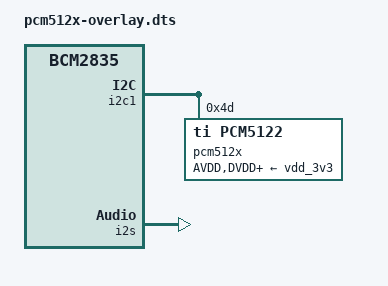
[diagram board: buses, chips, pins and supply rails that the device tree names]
/dts-v1/;
/plugin/;

/ {
    compatible = "brcm,bcm2835";

    fragment@0 {
        target = <&i2c1>;
        __overlay__ {
            #address-cells = <1>;
            #size-cells = <0>;
            status = "okay";

            pcm512x: pcm512x@4d {
                compatible = "ti,pcm5122";
                reg = <0x4d>;
                AVDD-supply = <&vdd_3v3>;
                DVDD-supply = <&vdd_3v3>;
                CPVDD-supply = <&vdd_3v3>;
                #sound-dai-cells = <0>;
            };
        };
    };

    fragment@1 {
        target = <&i2s>;
        __overlay__ {
            status = "okay";
        };
    };

    fragment@2 {
        target-path = "/";
        __overlay__ {
            pcm512x_sound: sound {
                compatible = "simple-audio-card";
                simple-audio-card,name = "RPI-PCM512x";
                simple-audio-card,format = "i2s";

                simple-audio-card,bitclock-master = <&cpu_dai>;
                simple-audio-card,frame-master = <&cpu_dai>;

                simple-audio-card,widgets =
                        "Speaker", "Speaker",
                        "Line", "Line Out";

                simple-audio-card,routing =
                        "Speaker", "OUTL",
                        "Speaker", "OUTR";

                simple-audio-card,cpu {
                    sound-dai = <&i2s>;
                };

                cpu_dai: simple-audio-card,codec {
                    sound-dai = <&pcm512x>;
                };
            };
        };
    };
};

